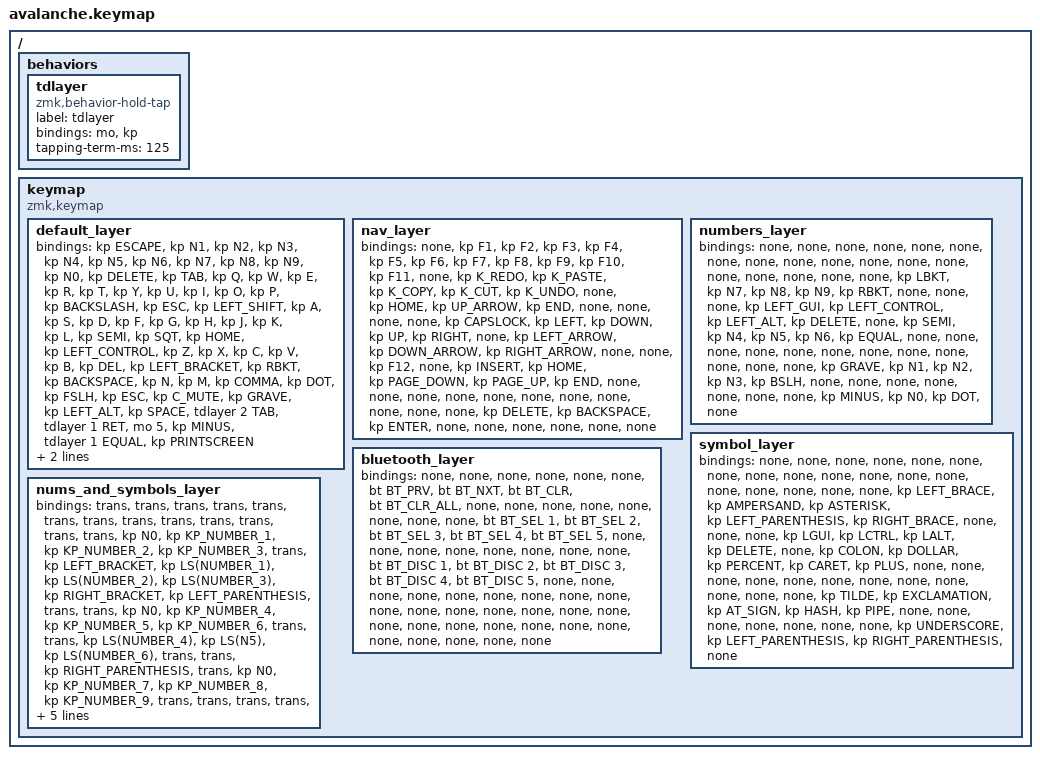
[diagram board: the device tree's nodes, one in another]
#include <behaviors.dtsi>
#include <dt-bindings/zmk/bt.h>
#include <dt-bindings/zmk/keys.h>

/ {
    behaviors {
        tdlayer: tdlayer {
            compatible = "zmk,behavior-hold-tap";
            #binding-cells = <2>;
            label = "tdlayer";
            bindings = <&mo>, <&kp>;

            tapping-term-ms = <125>;
        };
    };

    keymap {
        compatible = "zmk,keymap";

        /*
        &none  &none  &none  &none  &none  &none                                   &none  &none  &none  &none  &none  &none 
// ------------------------------------------------------------------------------------------------------------------------------------------------------------------------------------
        &none  &none  &none  &none  &none  &none                                   &none  &none  &none  &none  &none  &none 
// ------------------------------------------------------------------------------------------------------------------------------------------------------------------------------------
&none  &none  &none  &none  &none  &none  &none                                   &none  &none  &none  &none  &none  &none  &none 
// ------------------------------------------------------------------------------------------------------------------------------------------------------------------------------------
        &none  &none  &none  &none  &none  &none  &none  &none    &none &none  &none  &none  &none  &none  &none  &none 
// ------------------------------------------------------------------------------------------------------------------------------------------------------------------------------------
                                &none  &none  &none  &none  &none    &none &none  &none  &none  &none
*/

        default_layer {
            bindings = <
&kp ESCAPE  &kp N1  &kp N2  &kp N3  &kp N4  &kp N5  &kp N6  &kp N7  &kp N8  &kp N9  &kp N0  &kp DELETE  &kp TAB  &kp Q  &kp W  &kp E  &kp R  &kp T  &kp Y  &kp U  &kp I  &kp O  &kp P  &kp BACKSLASH  &kp ESC  &kp LEFT_SHIFT  &kp A  &kp S  &kp D  &kp F  &kp G  &kp H  &kp J  &kp K  &kp L  &kp SEMI  &kp SQT  &kp HOME  &kp LEFT_CONTROL  &kp Z  &kp X  &kp C  &kp V  &kp B  &kp DEL  &kp LEFT_BRACKET  &kp RBKT  &kp BACKSPACE  &kp N  &kp M  &kp COMMA  &kp DOT  &kp FSLH  &kp ESC  &kp C_MUTE  &kp GRAVE  &kp LEFT_ALT  &kp SPACE  &tdlayer 2 TAB  &tdlayer 1 RET  &mo 5  &kp MINUS  &tdlayer 1 EQUAL  &kp PRINTSCREEN
            >;

            sensor-bindings = <&inc_dec_kp C_VOL_UP C_VOL_DN &inc_dec_kp PG_UP PG_DN>;
        };

        nav_layer {
            bindings = <
&none  &kp F1  &kp F2  &kp F3  &kp F4  &kp F5  &kp F6  &kp F7  &kp F8  &kp F9  &kp F10  &kp F11  &none  &kp K_REDO  &kp K_PASTE  &kp K_COPY  &kp K_CUT  &kp K_UNDO  &none  &kp HOME  &kp UP_ARROW  &kp END  &none  &none  &none  &none  &kp CAPSLOCK  &kp LEFT  &kp DOWN  &kp UP  &kp RIGHT  &none  &kp LEFT_ARROW  &kp DOWN_ARROW  &kp RIGHT_ARROW  &none  &none  &kp F12  &none  &kp INSERT  &kp HOME  &kp PAGE_DOWN  &kp PAGE_UP  &kp END  &none  &none  &none  &none  &none  &none  &none  &none  &none  &none  &none  &kp DELETE  &kp BACKSPACE  &kp ENTER  &none  &none  &none  &none  &none  &none
            >;
        };

        numbers_layer {
            bindings = <
&none  &none  &none  &none  &none  &none  &none  &none  &none  &none  &none  &none  &none  &none  &none  &none  &none  &none  &kp LBKT  &kp N7  &kp N8  &kp N9  &kp RBKT  &none  &none  &none  &kp LEFT_GUI  &kp LEFT_CONTROL  &kp LEFT_ALT  &kp DELETE  &none  &kp SEMI  &kp N4  &kp N5  &kp N6  &kp EQUAL  &none  &none  &none  &none  &none  &none  &none  &none  &none  &none  &none  &none  &kp GRAVE  &kp N1  &kp N2  &kp N3  &kp BSLH  &none  &none  &none  &none  &none  &none  &none  &kp MINUS  &kp N0  &kp DOT  &none
            >;
        };

        symbol_layer {
            bindings = <
&none  &none  &none  &none  &none  &none  &none  &none  &none  &none  &none  &none  &none  &none  &none  &none  &none  &none  &kp LEFT_BRACE  &kp AMPERSAND  &kp ASTERISK  &kp LEFT_PARENTHESIS  &kp RIGHT_BRACE  &none  &none  &none  &kp LGUI  &kp LCTRL  &kp LALT  &kp DELETE  &none  &kp COLON  &kp DOLLAR  &kp PERCENT  &kp CARET  &kp PLUS  &none  &none  &none  &none  &none  &none  &none  &none  &none  &none  &none  &none  &kp TILDE  &kp EXCLAMATION  &kp AT_SIGN  &kp HASH  &kp PIPE  &none  &none  &none  &none  &none  &none  &none  &kp UNDERSCORE  &kp LEFT_PARENTHESIS  &kp RIGHT_PARENTHESIS  &none
            >;
        };

        bluetooth_layer {
            bindings = <
&none  &none  &none  &none  &none  &none  &bt BT_PRV  &bt BT_NXT  &bt BT_CLR  &bt BT_CLR_ALL  &none  &none  &none  &none  &none  &none  &none  &none  &bt BT_SEL 1  &bt BT_SEL 2  &bt BT_SEL 3  &bt BT_SEL 4  &bt BT_SEL 5  &none  &none  &none  &none  &none  &none  &none  &none  &bt BT_DISC 1  &bt BT_DISC 2  &bt BT_DISC 3  &bt BT_DISC 4  &bt BT_DISC 5  &none  &none  &none  &none  &none  &none  &none  &none  &none  &none  &none  &none  &none  &none  &none  &none  &none  &none  &none  &none  &none  &none  &none  &none  &none  &none  &none  &none
            >;
        };

        nums_and_symbols_layer {
            bindings = <
&trans  &trans  &trans  &trans  &trans  &trans  &trans  &trans  &trans  &trans  &trans  &trans  &trans  &kp N0  &kp KP_NUMBER_1  &kp KP_NUMBER_2  &kp KP_NUMBER_3  &trans  &kp LEFT_BRACKET  &kp LS(NUMBER_1)  &kp LS(NUMBER_2)  &kp LS(NUMBER_3)  &kp RIGHT_BRACKET  &kp LEFT_PARENTHESIS  &trans  &trans  &kp N0  &kp KP_NUMBER_4  &kp KP_NUMBER_5  &kp KP_NUMBER_6  &trans  &trans  &kp LS(NUMBER_4)  &kp LS(N5)  &kp LS(NUMBER_6)  &trans  &trans  &kp RIGHT_PARENTHESIS  &trans  &kp N0  &kp KP_NUMBER_7  &kp KP_NUMBER_8  &kp KP_NUMBER_9  &trans  &trans  &trans  &trans  &trans  &trans  &kp LS(NUMBER_7)  &kp LS(NUMBER_8)  &kp LS(NUMBER_9)  &kp LS(NUMBER_0)  &trans  &trans  &trans  &trans  &trans  &trans  &trans  &trans  &trans  &trans  &trans
            >;
        };
    };
};
